AUTOSAR XML (schema 4-2-1)
package /ComponentTypes
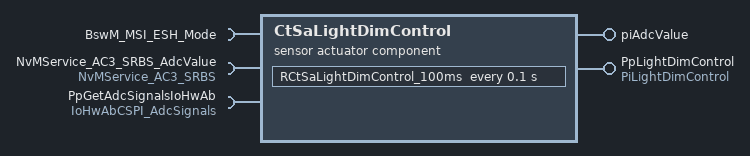
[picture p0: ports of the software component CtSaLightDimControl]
  sensor actuator sw component type CtSaLightDimControl
    provide port piAdcValue: nv-provide-com-spec{ram-block-init-value=255, variable=deAdcValue}, provided-interface=piAdcValue
    provide port PpLightDimControl: nonqueued-sender-com-spec{data-element=DeLightDimCtrl, init-value=constant-reference=CBackLightDimCtrlInit}, provided-interface=PiLightDimControl
    require port BswM_MSI_ESH_Mode: mode-switch-receiver-com-spec{enhanced-mode-api=false, supports-asynchronous-mode-switch=false}, required-interface=BswM_MSI_ESH_Mode
    require port NvMService_AC3_SRBS_AdcValue: required-com-specs=[EraseBlock, GetErrorStatus, InvalidateNvBlock, ReadBlock, SetRamBlockStatus, WriteBlock], required-interface=NvMService_AC3_SRBS
    require port PpGetAdcSignalsIoHwAb: client-com-spec=IoHwAb_Get_Adc_Signals, required-interface=IoHwAbCSPI_AdcSignals
    behavior CtSaLightDimControl_InternalBehavior: data-type-mapping=DemoTypeMapping
      timing event TMT_Dim_AdcNvMemory: start-on-event=RCtSaLightDimControl_100ms, period=0.1
        disabled-mode:
          BswM_MSI_ESH_Mode.BswM_MDGP_ESH_Mode.SHUTDOWN
          BswM_MSI_ESH_Mode.BswM_MDGP_ESH_Mode.STARTUP
          BswM_MSI_ESH_Mode.BswM_MDGP_ESH_Mode.WAKEUP
      runnable RCtSaLightDimControl_100ms: symbol=RCtSaLightDimControlDimAdcNvMemory
        data-send-points:
          access SEND_piAdcValue_AdcValue: accessed-variable=piAdcValue.deAdcValue
          access SEND_PpLightDimControl_DeLightDimCtrl: accessed-variable=PpLightDimControl.DeLightDimCtrl
        sync call SC_NvMService_AC3_SRBS_AdcValue_GetErrorStatus: operation=NvMService_AC3_SRBS_AdcValue.GetErrorStatus, timeout=0
        sync call SC_PpGetAdcSignalsIoHwAb_IoHwAb_Get_Adc_Signals: operation=PpGetAdcSignalsIoHwAb.IoHwAb_Get_Adc_Signals, timeout=0
  swc implementation CtSaLightDimControl_Implementation: behavior=CtSaLightDimControl_InternalBehavior
    code-descriptors:
      code Default: artifact-descriptors=autosar-engineering-object={short-label=Default, category=SWSRC}
